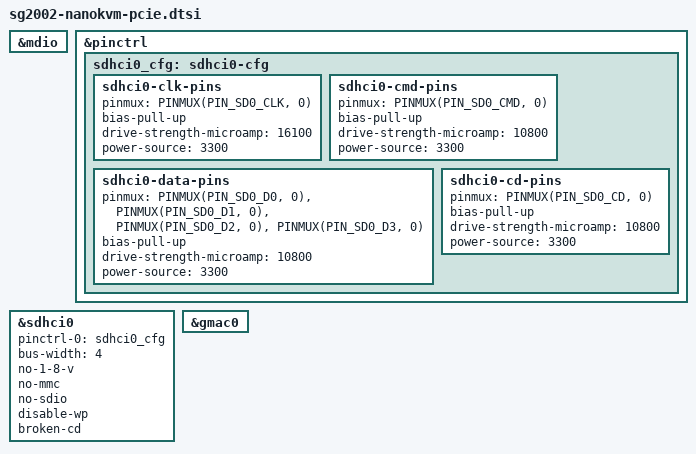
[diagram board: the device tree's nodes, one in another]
/* NanoKVM-PCIe carrier overlay (mainline).
 *
 * The SG2002 has an on-die GMAC (snps,dwmac-3.70a) at 0x4070000 with an
 * internal 10/100 EPHY reached through the mmioreg mdio-mux. The
 * upstream cv180x.dtsi defines both but leaves them `status =
 * "disabled"` (the LicheeRV-Nano dev board has no ethernet). The
 * NanoKVM-PCIe carrier wires the GMAC to the RJ45, so enable them.
 *
 * Layered on top of sg2002-licheerv-nano-bw.dtsi, which already keeps
 * SDIO1 (AIC8800 WiFi) enabled — so this DTB carries both ethernet and
 * WiFi for the PCIe board.
 */

&mdio {
	status = "okay";
};

/* SD card slot on sdhci0 (mmc@4310000). Upstream cv180x.dtsi leaves it
 * disabled and the base bw.dtsi only wires sdhci1 (SDIO/WiFi), so Linux
 * never saw the card — blocking both booting from SD and writing it.
 * Pins/props cribbed from upstream sg2002-licheerv-nano-b.dts. */
&pinctrl {
	sdhci0_cfg: sdhci0-cfg {
		sdhci0-clk-pins {
			pinmux = <PINMUX(PIN_SD0_CLK, 0)>;
			bias-pull-up;
			drive-strength-microamp = <16100>;
			power-source = <3300>;
		};
		sdhci0-cmd-pins {
			pinmux = <PINMUX(PIN_SD0_CMD, 0)>;
			bias-pull-up;
			drive-strength-microamp = <10800>;
			power-source = <3300>;
		};
		sdhci0-data-pins {
			pinmux = <PINMUX(PIN_SD0_D0, 0)>,
				 <PINMUX(PIN_SD0_D1, 0)>,
				 <PINMUX(PIN_SD0_D2, 0)>,
				 <PINMUX(PIN_SD0_D3, 0)>;
			bias-pull-up;
			drive-strength-microamp = <10800>;
			power-source = <3300>;
		};
		sdhci0-cd-pins {
			pinmux = <PINMUX(PIN_SD0_CD, 0)>;
			bias-pull-up;
			drive-strength-microamp = <10800>;
			power-source = <3300>;
		};
	};
};

&sdhci0 {
	pinctrl-0 = <&sdhci0_cfg>;
	pinctrl-names = "default";
	status = "okay";
	bus-width = <4>;
	no-1-8-v;
	no-mmc;
	no-sdio;
	disable-wp;
	/* The SD0_CD card-detect line is unreliable on this carrier (it
	 * intermittently reports "no card" after a power-cycle, so the
	 * kernel never probes an inserted card). Ignore CD and poll the
	 * slot directly. */
	broken-cd;
};

&gmac0 {
	/* Just enable the node; the phy-mode (rmii) and the internal-EPHY
	 * mdio-mux come from the upstream include chain. The earlier -EINVAL
	 * ("validation of rmii/internal ... failed") was NOT a phy-mode
	 * problem: the internal EPHY was still shut down, so MDIO read no
	 * abilities and the MAC/PHY speed-cap intersection came out empty.
	 * Our dwmac-sophgo patch 0013 powers the EPHY up in probe (it then
	 * answers MDIO with phy_id 0x00435649), after which the Generic PHY
	 * attaches and validates against the dwmac1000 10/100 caps. */
	status = "okay";
};
